AUTOSAR XML (schema 00051)
package /Components
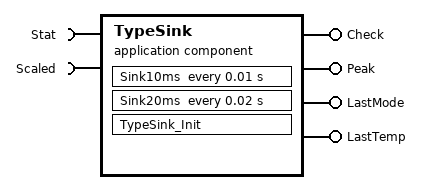
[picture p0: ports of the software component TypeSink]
  application sw component type TypeSink
    require port Stat: nonqueued-receiver-com-spec=Stat, required-interface=Stat
    require port Scaled: nonqueued-receiver-com-spec=Scaled, required-interface=Scaled
    4 x provide port:
      Check: nonqueued-sender-com-spec{data-element=Check, init-value=7}, provided-interface=Check
      Peak: nonqueued-sender-com-spec=Peak, provided-interface=Peak
      LastMode: nonqueued-sender-com-spec{data-element=LastMode, init-value=TypeSwc_Mode_Run}, provided-interface=LastMode
      LastTemp: nonqueued-sender-com-spec{data-element=LastTemp, init-value=25.5}, provided-interface=LastTemp
    behavior TypeSink_IB
      timing event Event_Sink10ms: start-on-event=Sink10ms, period=0.01
      timing event Event_Sink20ms: start-on-event=Sink20ms, period=0.02
      runnable TypeSink_Init
        data-send-points:
          access OUT_Check_Check: accessed-variable=Check.Check
      runnable Sink10ms
        data-receive-point-by-arguments:
          access IN_Scaled_Scaled: accessed-variable=Scaled.Scaled
        data-send-points:
          access OUT_Peak_Peak: accessed-variable=Peak.Peak
      runnable Sink20ms
        data-receive-point-by-arguments:
          access IN_Stat_Stat: accessed-variable=Stat.Stat
          access IN_Scaled_Scaled: accessed-variable=Scaled.Scaled
        data-send-points:
          access OUT_Check_Check: accessed-variable=Check.Check
          access OUT_LastMode_LastMode: accessed-variable=LastMode.LastMode
package /Interfaces
  6 x sender receiver interface:
    Stat
      data Stat: type=TypeSwc_StatBus
    Scaled
      data Scaled: type=rt_Array_uint16_4
    Check
      data Check: type=uint32
    Peak
      data Peak: type=uint16
    LastMode
      data LastMode: type=TypeSwc_Mode
    LastTemp
      data LastTemp: type=UFIX16_SP1_BN40
